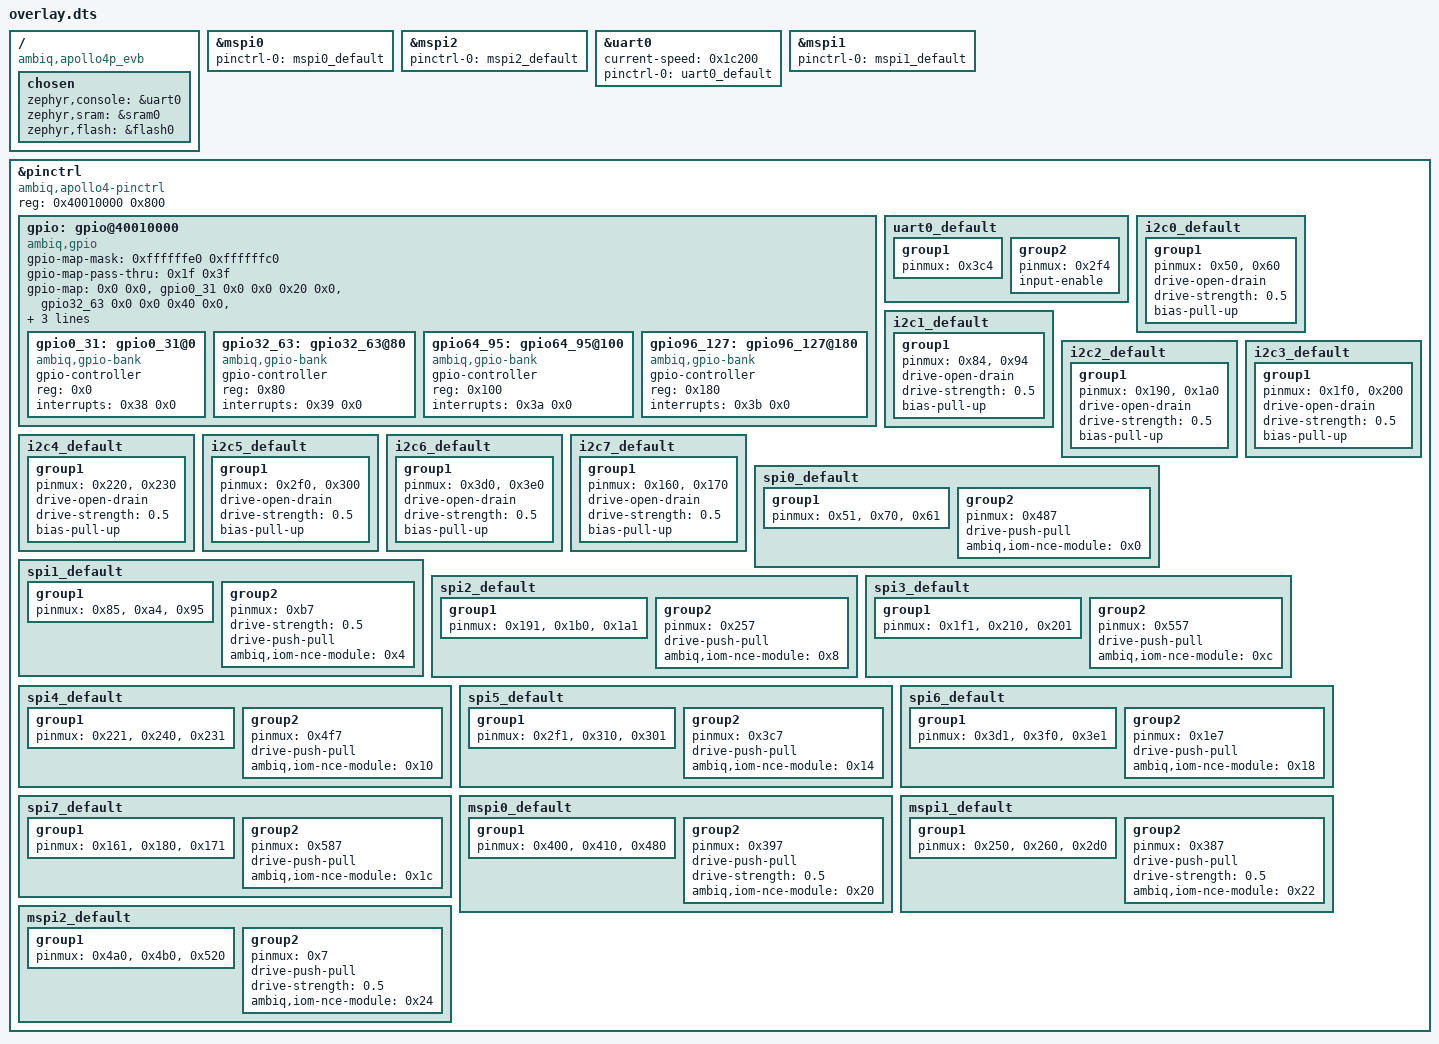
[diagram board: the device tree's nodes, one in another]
/ {
	compatible = "ambiq,apollo4p_evb";
	chosen {
		zephyr,console = &uart0;
		zephyr,sram = &sram0;
		zephyr,flash = &flash0;
	};
};
&gpio64_95{
	status = "okay";
};
&gpio96_127{
	status = "okay";
};
&gpio32_63{
	status = "okay";
};
&mspi0{
	status = "okay";
	pinctrl-0 = < &mspi0_default >;
	pinctrl-names = "default";
};
&mspi2{
	status = "okay";
	pinctrl-0 = < &mspi2_default >;
	pinctrl-names = "default";
};
&uart0{
	status = "okay";
	current-speed = < 0x1c200 >;
	pinctrl-0 = < &uart0_default >;
	pinctrl-names = "default";
};
&gpio0_31{
	status = "okay";
};
&mspi1{
	status = "okay";
	pinctrl-0 = < &mspi1_default >;
	pinctrl-names = "default";
};
&pinctrl{
	compatible = "ambiq,apollo4-pinctrl";
	reg = < 0x40010000 0x800 >;
	#address-cells = < 0x1 >;
	#size-cells = < 0x0 >;
	gpio: gpio@40010000 {
		compatible = "ambiq,gpio";
		gpio-map-mask = < 0xffffffe0 0xffffffc0 >;
		gpio-map-pass-thru = < 0x1f 0x3f >;
		gpio-map = < 0x0 0x0 &gpio0_31 0x0 0x0 0x20 0x0 &gpio32_63 0x0 0x0 0x40 0x0 &gpio64_95 0x0 0x0 0x60 0x0 &gpio96_127 0x0 0x0 >;
		reg = < 0x40010000 >;
		#gpio-cells = < 0x2 >;
		#address-cells = < 0x1 >;
		#size-cells = < 0x0 >;
		ranges;
		gpio0_31: gpio0_31@0 {
			compatible = "ambiq,gpio-bank";
			gpio-controller;
			#gpio-cells = < 0x2 >;
			reg = < 0x0 >;
			interrupts = < 0x38 0x0 >;
			status = "okay";
			phandle = < 0xa >;
		};
		gpio32_63: gpio32_63@80 {
			compatible = "ambiq,gpio-bank";
			gpio-controller;
			#gpio-cells = < 0x2 >;
			reg = < 0x80 >;
			interrupts = < 0x39 0x0 >;
			status = "okay";
			phandle = < 0xb >;
		};
		gpio64_95: gpio64_95@100 {
			compatible = "ambiq,gpio-bank";
			gpio-controller;
			#gpio-cells = < 0x2 >;
			reg = < 0x100 >;
			interrupts = < 0x3a 0x0 >;
			status = "okay";
			phandle = < 0xc >;
		};
		gpio96_127: gpio96_127@180 {
			compatible = "ambiq,gpio-bank";
			gpio-controller;
			#gpio-cells = < 0x2 >;
			reg = < 0x180 >;
			interrupts = < 0x3b 0x0 >;
			status = "okay";
			phandle = < 0xd >;
		};
	};
	uart0_default: uart0_default {
		group1 {
			pinmux = < 0x3c4 >;
		};
		group2 {
			pinmux = < 0x2f4 >;
			input-enable;
		};
	};
	i2c0_default: i2c0_default {
		group1 {
			pinmux = < 0x50 >, < 0x60 >;
			drive-open-drain;
			drive-strength = "0.5";
			bias-pull-up;
		};
	};
	i2c1_default: i2c1_default {
		group1 {
			pinmux = < 0x84 >, < 0x94 >;
			drive-open-drain;
			drive-strength = "0.5";
			bias-pull-up;
		};
	};
	i2c2_default: i2c2_default {
		group1 {
			pinmux = < 0x190 >, < 0x1a0 >;
			drive-open-drain;
			drive-strength = "0.5";
			bias-pull-up;
		};
	};
	i2c3_default: i2c3_default {
		group1 {
			pinmux = < 0x1f0 >, < 0x200 >;
			drive-open-drain;
			drive-strength = "0.5";
			bias-pull-up;
		};
	};
	i2c4_default: i2c4_default {
		group1 {
			pinmux = < 0x220 >, < 0x230 >;
			drive-open-drain;
			drive-strength = "0.5";
			bias-pull-up;
		};
	};
	i2c5_default: i2c5_default {
		group1 {
			pinmux = < 0x2f0 >, < 0x300 >;
			drive-open-drain;
			drive-strength = "0.5";
			bias-pull-up;
		};
	};
	i2c6_default: i2c6_default {
		group1 {
			pinmux = < 0x3d0 >, < 0x3e0 >;
			drive-open-drain;
			drive-strength = "0.5";
			bias-pull-up;
		};
	};
	i2c7_default: i2c7_default {
		group1 {
			pinmux = < 0x160 >, < 0x170 >;
			drive-open-drain;
			drive-strength = "0.5";
			bias-pull-up;
		};
	};
	spi0_default: spi0_default {
		group1 {
			pinmux = < 0x51 >, < 0x70 >, < 0x61 >;
		};
		group2 {
			pinmux = < 0x487 >;
			drive-push-pull;
			ambiq,iom-nce-module = < 0x0 >;
		};
	};
	spi1_default: spi1_default {
		group1 {
			pinmux = < 0x85 >, < 0xa4 >, < 0x95 >;
		};
		group2 {
			pinmux = < 0xb7 >;
			drive-strength = "0.5";
			drive-push-pull;
			ambiq,iom-nce-module = < 0x4 >;
		};
	};
	spi2_default: spi2_default {
		group1 {
			pinmux = < 0x191 >, < 0x1b0 >, < 0x1a1 >;
		};
		group2 {
			pinmux = < 0x257 >;
			drive-push-pull;
			ambiq,iom-nce-module = < 0x8 >;
		};
	};
	spi3_default: spi3_default {
		group1 {
			pinmux = < 0x1f1 >, < 0x210 >, < 0x201 >;
		};
		group2 {
			pinmux = < 0x557 >;
			drive-push-pull;
			ambiq,iom-nce-module = < 0xc >;
		};
	};
	spi4_default: spi4_default {
		group1 {
			pinmux = < 0x221 >, < 0x240 >, < 0x231 >;
		};
		group2 {
			pinmux = < 0x4f7 >;
			drive-push-pull;
			ambiq,iom-nce-module = < 0x10 >;
		};
	};
	spi5_default: spi5_default {
		group1 {
			pinmux = < 0x2f1 >, < 0x310 >, < 0x301 >;
		};
		group2 {
			pinmux = < 0x3c7 >;
			drive-push-pull;
			ambiq,iom-nce-module = < 0x14 >;
		};
	};
	spi6_default: spi6_default {
		group1 {
			pinmux = < 0x3d1 >, < 0x3f0 >, < 0x3e1 >;
		};
		group2 {
			pinmux = < 0x1e7 >;
			drive-push-pull;
			ambiq,iom-nce-module = < 0x18 >;
		};
	};
	spi7_default: spi7_default {
		group1 {
			pinmux = < 0x161 >, < 0x180 >, < 0x171 >;
		};
		group2 {
			pinmux = < 0x587 >;
			drive-push-pull;
			ambiq,iom-nce-module = < 0x1c >;
		};
	};
	mspi0_default: mspi0_default {
		group1 {
			pinmux = < 0x400 >, < 0x410 >, < 0x480 >;
		};
		group2 {
			pinmux = < 0x397 >;
			drive-push-pull;
			drive-strength = "0.5";
			ambiq,iom-nce-module = < 0x20 >;
		};
	};
	mspi1_default: mspi1_default {
		group1 {
			pinmux = < 0x250 >, < 0x260 >, < 0x2d0 >;
		};
		group2 {
			pinmux = < 0x387 >;
			drive-push-pull;
			drive-strength = "0.5";
			ambiq,iom-nce-module = < 0x22 >;
		};
	};
	mspi2_default: mspi2_default {
		group1 {
			pinmux = < 0x4a0 >, < 0x4b0 >, < 0x520 >;
		};
		group2 {
			pinmux = < 0x7 >;
			drive-push-pull;
			drive-strength = "0.5";
			ambiq,iom-nce-module = < 0x24 >;
		};
	};
};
